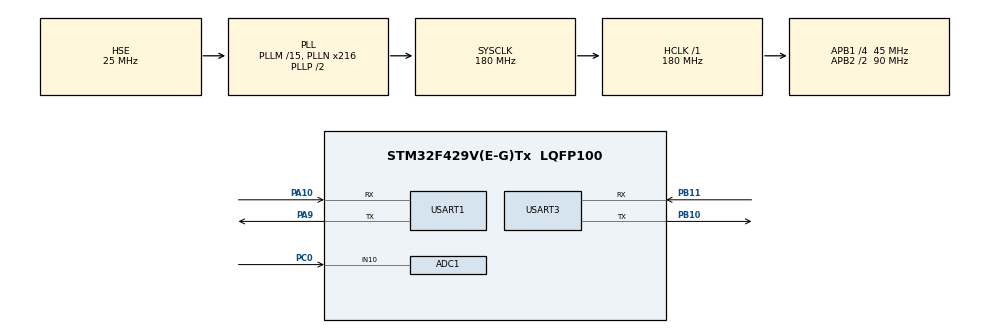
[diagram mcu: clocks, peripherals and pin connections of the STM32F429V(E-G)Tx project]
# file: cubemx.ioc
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ADC1.Channel-1\#ChannelRegularConversion=ADC_CHANNEL_10
ADC1.ContinuousConvMode=ENABLE
ADC1.DMAContinuousRequests=ENABLE
ADC1.NbrOfConversionFlag=1
ADC1.Rank-1\#ChannelRegularConversion=1
ADC1.SamplingTime-1\#ChannelRegularConversion=ADC_SAMPLETIME_28CYCLES
ADC1.master=1
Dma.ADC1.1.Direction=DMA_PERIPH_TO_MEMORY
Dma.ADC1.1.FIFOMode=DMA_FIFOMODE_DISABLE
Dma.ADC1.1.Instance=DMA2_Stream0
Dma.ADC1.1.MemDataAlignment=DMA_MDATAALIGN_WORD
Dma.ADC1.1.MemInc=DMA_MINC_ENABLE
Dma.ADC1.1.Mode=DMA_CIRCULAR
Dma.ADC1.1.PeriphDataAlignment=DMA_PDATAALIGN_WORD
Dma.ADC1.1.PeriphInc=DMA_PINC_DISABLE
Dma.ADC1.1.Priority=DMA_PRIORITY_LOW
Dma.Request0=USART3_RX
Dma.Request1=ADC1
Dma.USART3_RX.0.Direction=DMA_PERIPH_TO_MEMORY
Dma.USART3_RX.0.FIFOMode=DMA_FIFOMODE_DISABLE
Dma.USART3_RX.0.Instance=DMA1_Stream1
Dma.USART3_RX.0.MemDataAlignment=DMA_MDATAALIGN_BYTE
Dma.USART3_RX.0.MemInc=DMA_MINC_ENABLE
Dma.USART3_RX.0.Mode=DMA_NORMAL
Dma.USART3_RX.0.PeriphDataAlignment=DMA_PDATAALIGN_BYTE
Dma.USART3_RX.0.PeriphInc=DMA_PINC_DISABLE
Dma.USART3_RX.0.Priority=DMA_PRIORITY_LOW
Mcu.Family=STM32F4
Mcu.Name=STM32F429V(E-G)Tx
Mcu.Package=LQFP100
NVIC.DMA1_Stream1_IRQn=true\:0\:0\:false\:false\:true\:false\:true\:true
NVIC.DMA2_Stream0_IRQn=true\:0\:0\:false\:false\:true\:false\:true\:true
NVIC.PriorityGroup=NVIC_PRIORITYGROUP_4
NVIC.USART1_IRQn=true\:0\:0\:false\:false\:true\:true\:true\:true
NVIC.USART3_IRQn=true\:0\:0\:false\:false\:true\:true\:true\:true
PA10.Mode=Asynchronous
PA10.Signal=USART1_RX
PA13.Mode=Serial_Wire
PA13.Signal=SYS_JTMS-SWDIO
PA14.Mode=Serial_Wire
PA14.Signal=SYS_JTCK-SWCLK
PA9.Mode=Asynchronous
PA9.Signal=USART1_TX
PB10.Mode=Asynchronous
PB10.Signal=USART3_TX
PB11.Mode=Asynchronous
PB11.Signal=USART3_RX
PC0.Signal=ADCx_IN10
PC14/OSC32_IN.Mode=LSE-External-Oscillator
PC14/OSC32_IN.Signal=RCC_OSC32_IN
PC15/OSC32_OUT.Mode=LSE-External-Oscillator
PC15/OSC32_OUT.Signal=RCC_OSC32_OUT
PH0/OSC_IN.Mode=HSE-External-Oscillator
PH0/OSC_IN.Signal=RCC_OSC_IN
PH1/OSC_OUT.Mode=HSE-External-Oscillator
PH1/OSC_OUT.Signal=RCC_OSC_OUT
ProjectManager.HeapSize=0x200
ProjectManager.StackSize=0x400
ProjectManager.TargetToolchain=MDK-ARM V5.32
RCC.48MHZClocksFreq_Value=90000000
RCC.AHBFreq_Value=180000000
RCC.APB1CLKDivider=RCC_HCLK_DIV4
RCC.APB1Freq_Value=45000000
RCC.APB1TimFreq_Value=90000000
RCC.APB2CLKDivider=RCC_HCLK_DIV2
RCC.APB2Freq_Value=90000000
RCC.APB2TimFreq_Value=180000000
RCC.CortexFreq_Value=180000000
RCC.HCLKFreq_Value=180000000
RCC.HSE_VALUE=25000000
RCC.HSI_VALUE=16000000
RCC.PLLM=15
RCC.PLLN=216
RCC.PLLSourceVirtual=RCC_PLLSOURCE_HSE
RCC.SYSCLKFreq_VALUE=180000000
RCC.SYSCLKSource=RCC_SYSCLKSOURCE_PLLCLK
RCC.VCOOutputFreq_Value=360000000
SH.ADCx_IN10.0=ADC1_IN10,IN10
USART1.VirtualMode=VM_ASYNC
USART3.VirtualMode=VM_ASYNC
board=custom

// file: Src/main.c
/* USER CODE BEGIN Header */
/**
  ******************************************************************************
  * @file           : main.c
  * @brief          : Main program body
  ******************************************************************************
  * @attention
  *
  * Copyright (c) 2026 STMicroelectronics.
  * All rights reserved.
  *
  * This software is licensed under terms that can be found in the LICENSE file
  * in the root directory of this software component.
  * If no LICENSE file comes with this software, it is provided AS-IS.
  *
  ******************************************************************************
  */
/* USER CODE END Header */
#include "main.h"
#include "adc.h"
#include "dma.h"
#include "usart.h"
#include "gpio.h"

/* USER CODE BEGIN Includes */
#include "mydefine.h"
/* USER CODE END Includes */

void SystemClock_Config(void);

__WEAK int main(void)
{

  /* MCU Configuration--------------------------------------------------------*/

  /* Reset of all peripherals, Initializes the Flash interface and the Systick. */
  HAL_Init();

  /* Configure the system clock */
  SystemClock_Config();

  /* Initialize all configured peripherals */
  MX_GPIO_Init();
  MX_DMA_Init();
  MX_USART1_UART_Init();
  MX_USART3_UART_Init();
  MX_ADC1_Init();

  /* Infinite loop */
  while (1)
  {

  }
}

void SystemClock_Config(void)
{
  RCC_OscInitTypeDef RCC_OscInitStruct = {0};
  RCC_ClkInitTypeDef RCC_ClkInitStruct = {0};

  /** Configure the main internal regulator output voltage
  */
  __HAL_RCC_PWR_CLK_ENABLE();
  __HAL_PWR_VOLTAGESCALING_CONFIG(PWR_REGULATOR_VOLTAGE_SCALE1);

  /** Initializes the RCC Oscillators according to the specified parameters
  * in the RCC_OscInitTypeDef structure.
  */
  RCC_OscInitStruct.OscillatorType = RCC_OSCILLATORTYPE_HSE;
  RCC_OscInitStruct.HSEState = RCC_HSE_ON;
  RCC_OscInitStruct.PLL.PLLState = RCC_PLL_ON;
  RCC_OscInitStruct.PLL.PLLSource = RCC_PLLSOURCE_HSE;
  RCC_OscInitStruct.PLL.PLLM = 15;
  RCC_OscInitStruct.PLL.PLLN = 216;
  RCC_OscInitStruct.PLL.PLLP = RCC_PLLP_DIV2;
  RCC_OscInitStruct.PLL.PLLQ = 4;
  if (HAL_RCC_OscConfig(&RCC_OscInitStruct) != HAL_OK)
  {
    Error_Handler();
  }

  /** Activate the Over-Drive mode
  */
  if (HAL_PWREx_EnableOverDrive() != HAL_OK)
  {
    Error_Handler();
  }

  /** Initializes the CPU, AHB and APB buses clocks
  */
  RCC_ClkInitStruct.ClockType = RCC_CLOCKTYPE_HCLK|RCC_CLOCKTYPE_SYSCLK
                              |RCC_CLOCKTYPE_PCLK1|RCC_CLOCKTYPE_PCLK2;
  RCC_ClkInitStruct.SYSCLKSource = RCC_SYSCLKSOURCE_PLLCLK;
  RCC_ClkInitStruct.AHBCLKDivider = RCC_SYSCLK_DIV1;
  RCC_ClkInitStruct.APB1CLKDivider = RCC_HCLK_DIV4;
  RCC_ClkInitStruct.APB2CLKDivider = RCC_HCLK_DIV2;

  if (HAL_RCC_ClockConfig(&RCC_ClkInitStruct, FLASH_LATENCY_5) != HAL_OK)
  {
    Error_Handler();
  }
}

//void Error_Handler(void)
//{
//  /* USER CODE BEGIN Error_Handler_Debug */
//  /* User can add his own implementation to report the HAL error return state */
//  __disable_irq();
//  while (1)
//  {
//  }
//  /* USER CODE END Error_Handler_Debug */
//}
